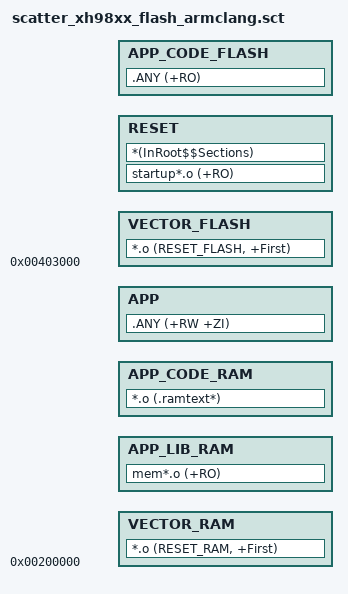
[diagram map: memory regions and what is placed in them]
#! armclang -E --target=arm-arm-none-eabi -mcpu=cortex-m7 -xc
; ***************************************************************
; *** Scatter-Loading Description File generated by Xihao ***
; ***************************************************************

FLASH_LOAD 0x00403000 0x00800000
{
    ; Vector in Flash
    VECTOR_FLASH 0x00403000
    {
        *.o (RESET_FLASH, +First)
    }

    ; Startup and Keil Root code in Flash
    RESET +0
    {
        startup*.o (+RO)
        *(InRoot$$Sections)
    }

    ; Other Code in Flash
    APP_CODE_FLASH +0
    {
        .ANY (+RO)
    }

    ; Vector in RAM
    VECTOR_RAM 0x00200000
    {
        *.o (RESET_RAM, +First)
    }

    ; Critical library code in RAM
    APP_LIB_RAM +0
    {
        mem*.o (+RO)
        ; *mc_w.l (+RO)
        ; *mf_w.l (+RO)
    }

    ; User critical code in RAM
    APP_CODE_RAM +0
    {
        *.o (.ramtext*)
        ; main.o (+RO)
    }

    ; Data in RAM
    APP 0x20000000 + AlignExpr(ImageLimit(APP_CODE_RAM), 16) - 0x00200000
    {
        .ANY (+RW +ZI)
    }

}

ScatterAssert(ImageLimit(RESET) < (0x00403000+0x00002000))
ScatterAssert(ImageLimit(APP)   < (0x20000000+0x00009790))

